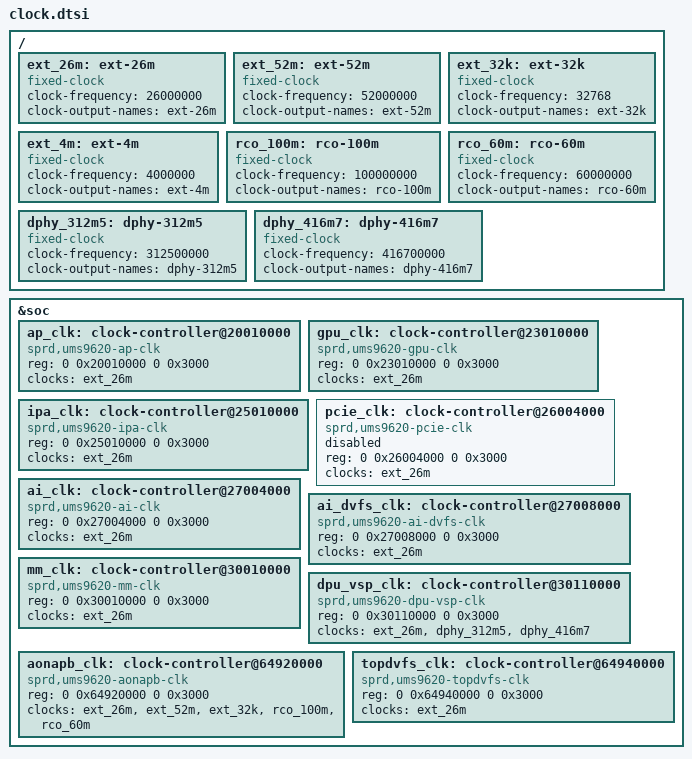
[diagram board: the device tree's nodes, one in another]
&soc {
	ap_clk: clock-controller@20010000 {
		compatible = "sprd,ums9620-ap-clk";
		reg = <0 0x20010000 0 0x3000>;
		clocks = <&ext_26m>;
		clock-names = "ext-26m";
		#clock-cells = <1>;
	};

	gpu_clk: clock-controller@23010000 {
		compatible = "sprd,ums9620-gpu-clk";
		reg = <0 0x23010000 0 0x3000>;
		clocks = <&ext_26m>;
		clock-names = "ext-26m";
		#clock-cells = <1>;
	};

	ipa_clk: clock-controller@25010000 {
		compatible = "sprd,ums9620-ipa-clk";
		reg = <0 0x25010000 0 0x3000>;
		clocks = <&ext_26m>;
		clock-names = "ext-26m";
		#clock-cells = <1>;
	};

	pcie_clk: clock-controller@26004000 {
		compatible = "sprd,ums9620-pcie-clk";
		reg = <0 0x26004000 0 0x3000>;
		clocks = <&ext_26m>;
		clock-names = "ext-26m";
		#clock-cells = <1>;
		status = "disable";
	};

	ai_clk: clock-controller@27004000 {
		compatible = "sprd,ums9620-ai-clk";
		reg = <0 0x27004000 0 0x3000>;
		clocks = <&ext_26m>;
		clock-names = "ext-26m";
		#clock-cells = <1>;
	};

	ai_dvfs_clk: clock-controller@27008000 {
		compatible = "sprd,ums9620-ai-dvfs-clk";
		reg = <0 0x27008000 0 0x3000>;
		clocks = <&ext_26m>;
		clock-names = "ext-26m";
		#clock-cells = <1>;
	};

	mm_clk: clock-controller@30010000 {
		compatible = "sprd,ums9620-mm-clk";
		reg = <0 0x30010000 0 0x3000>;
		clocks = <&ext_26m>;
		clock-names = "ext-26m";
		#clock-cells = <1>;
	};

	dpu_vsp_clk: clock-controller@30110000 {
		compatible = "sprd,ums9620-dpu-vsp-clk";
		reg = <0 0x30110000 0 0x3000>;
		clocks = <&ext_26m>, <&dphy_312m5>, <&dphy_416m7>;
		clock-names = "ext-26m", "dphy-312m5", "dphy-416m7";
		#clock-cells = <1>;
	};

	aonapb_clk: clock-controller@64920000 {
		compatible = "sprd,ums9620-aonapb-clk";
		reg = <0 0x64920000 0 0x3000>;
		clocks = <&ext_26m>, <&ext_52m>, <&ext_32k>, <&rco_100m>, <&rco_60m>;
		clock-names = "ext-26m", "ext-52m", "ext-32k", "rco-100m", "rco-60m";
		#clock-cells = <1>;
	};

	topdvfs_clk: clock-controller@64940000 {
		compatible = "sprd,ums9620-topdvfs-clk";
		reg = <0 0x64940000 0 0x3000>;
		clocks = <&ext_26m>;
		clock-names = "ext-26m";
		#clock-cells = <1>;
	};
};

/ {
	ext_26m: ext-26m {
		compatible = "fixed-clock";
		#clock-cells = <0>;
		clock-frequency = <26000000>;
		clock-output-names = "ext-26m";
	};

	ext_52m: ext-52m {
		compatible = "fixed-clock";
		#clock-cells = <0>;
		clock-frequency = <52000000>;
		clock-output-names = "ext-52m";
	};

	ext_32k: ext-32k {
		compatible = "fixed-clock";
		#clock-cells = <0>;
		clock-frequency = <32768>;
		clock-output-names = "ext-32k";
	};

	ext_4m: ext-4m {
		compatible = "fixed-clock";
		#clock-cells = <0>;
		clock-frequency = <4000000>;
		clock-output-names = "ext-4m";
	};

	rco_100m: rco-100m {
		compatible = "fixed-clock";
		#clock-cells = <0>;
		clock-frequency = <100000000>;
		clock-output-names = "rco-100m";
	};

	rco_60m: rco-60m {
		compatible = "fixed-clock";
		#clock-cells = <0>;
		clock-frequency = <60000000>;
		clock-output-names = "rco-60m";
        };

	dphy_312m5: dphy-312m5 {
		compatible = "fixed-clock";
		#clock-cells = <0>;
		clock-frequency = <312500000>;
		clock-output-names = "dphy-312m5";
	};

	dphy_416m7: dphy-416m7 {
		compatible = "fixed-clock";
		#clock-cells = <0>;
		clock-frequency = <416700000>;
		clock-output-names = "dphy-416m7";
	};
};
